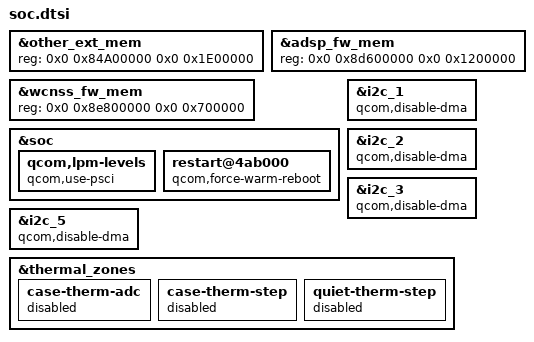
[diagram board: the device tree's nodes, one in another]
/* msm8953.dtsi */
&other_ext_mem {
	reg = <0x0 0x84A00000 0x0 0x1E00000>;
};
&adsp_fw_mem {
	reg = <0x0 0x8d600000 0x0 0x1200000>;
};
&wcnss_fw_mem {
	reg = <0x0 0x8e800000 0x0 0x700000>;
};

&soc {
	qcom,lpm-levels {
		qcom,use-psci;
	};

	restart@4ab000 {
		qcom,force-warm-reboot;
	};
};

&i2c_1 {
	qcom,disable-dma;
};

&i2c_2 {
	qcom,disable-dma;
};

&i2c_3 {
	qcom,disable-dma;
};

&i2c_5 {
	qcom,disable-dma;
};

&thermal_zones {
	case-therm-adc {
		status = "disabled";
	};

	case-therm-step {
		status = "disabled";
	};

	quiet-therm-step {
		status = "disabled";
	};
};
